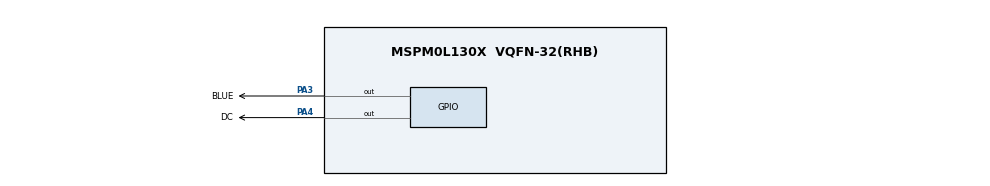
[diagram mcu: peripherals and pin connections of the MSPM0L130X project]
/**
 * @cliArgs --device "MSPM0L130X" --package "VQFN-32(RHB)" --part "Default" --product "mspm0_sdk@1.20.01.06"
 * @versions {"tool":"1.18.1+3343"}
 */

/**
 * Import the modules used in this configuration.
 */
const Board  = scripting.addModule("/ti/driverlib/Board");
const GPIO   = scripting.addModule("/ti/driverlib/GPIO", {}, false);
const GPIO1  = GPIO.addInstance();
const GPIO2  = GPIO.addInstance();
const SPI    = scripting.addModule("/ti/driverlib/SPI", {}, false);
const SPI1   = SPI.addInstance();
const SYSCTL = scripting.addModule("/ti/driverlib/SYSCTL");
const UART   = scripting.addModule("/ti/driverlib/UART", {}, false);
const UART1  = UART.addInstance();

/**
 * Write custom configuration values to the imported modules.
 */
const gate6  = system.clockTree["MFCLKGATE"];
gate6.enable = true;

const gate7  = system.clockTree["MFPCLKGATE"];
gate7.enable = true;


GPIO1.$name                          = "LED";
GPIO1.associatedPins[0].$name        = "BLUE";
GPIO1.associatedPins[0].initialValue = "SET";
GPIO1.associatedPins[0].pin.$assign  = "PA3";

GPIO2.$name                         = "OLED";
GPIO2.associatedPins[0].$name       = "DC";
GPIO2.associatedPins[0].pin.$assign = "PA4";

SPI1.$name               = "SPI_0";
SPI1.sclkPinConfig.$name = "ti_driverlib_gpio_GPIOPinGeneric2";
SPI1.mosiPinConfig.$name = "ti_driverlib_gpio_GPIOPinGeneric3";
SPI1.misoPinConfig.$name = "ti_driverlib_gpio_GPIOPinGeneric4";
SPI1.cs0PinConfig.$name  = "ti_driverlib_gpio_GPIOPinGeneric5";

SYSCTL.MFCLKEn     = true;
SYSCTL.MFPCLKEn    = true;
SYSCTL.clockTreeEn = true;

UART1.$name                            = "UART_1";
UART1.enabledInterrupts                = ["RX"];
UART1.targetBaudRate                   = 800000;
UART1.peripheral.$assign               = "UART0";
UART1.txPinConfig.direction            = scripting.forceWrite("OUTPUT");
UART1.txPinConfig.hideOutputInversion  = scripting.forceWrite(false);
UART1.txPinConfig.onlyInternalResistor = scripting.forceWrite(false);
UART1.txPinConfig.passedPeripheralType = scripting.forceWrite("Digital");
UART1.txPinConfig.$name                = "ti_driverlib_gpio_GPIOPinGeneric0";
UART1.rxPinConfig.hideOutputInversion  = scripting.forceWrite(false);
UART1.rxPinConfig.onlyInternalResistor = scripting.forceWrite(false);
UART1.rxPinConfig.passedPeripheralType = scripting.forceWrite("Digital");
UART1.rxPinConfig.$name                = "ti_driverlib_gpio_GPIOPinGeneric1";

/**
 * Pinmux solution for unlocked pins/peripherals. This ensures that minor changes to the automatic solver in a future
 * version of the tool will not impact the pinmux you originally saw.  These lines can be completely deleted in order to
 * re-solve from scratch.
 */
Board.peripheral.$suggestSolution          = "DEBUGSS";
Board.peripheral.swclkPin.$suggestSolution = "PA20";
Board.peripheral.swdioPin.$suggestSolution = "PA19";
SPI1.peripheral.$suggestSolution           = "SPI0";
SPI1.peripheral.sclkPin.$suggestSolution   = "PA11";
SPI1.peripheral.mosiPin.$suggestSolution   = "PA18";
SPI1.peripheral.misoPin.$suggestSolution   = "PA10";
SPI1.peripheral.cs0Pin.$suggestSolution    = "PA2";
UART1.peripheral.rxPin.$suggestSolution    = "PA22";
UART1.peripheral.txPin.$suggestSolution    = "PA17/OPA1.IN0-";
